# ATSAMG53N19 device description
Architecture: CORTEX-M4; Family: SAMG; Series: SAMG53
Registers are 32-bit, read-write, no defined reset value unless marked. A register's access mark holds for its fields unless they carry their own. Offsets are from the block's base; [hi:lo] are bit positions; {n}, {i} and the like mark numbered series; 'fields as' and 'values as' point back to an identical list; <NAME> marks a mode.

## USART — Universal Synchronous Asynchronous Receiver Transmitter
Instances: USART 0x40024000
0x00 US_CR wo (modes: USART when US_MR.USART_MODE=None; SPI when US_MR.USART_MODE=None) — Control Register
  [19] RCS <SPI> — Release SPI Chip Select
  [18] FCS <SPI> — Force SPI Chip Select
  [8] RSTSTA <SPI> — Reset Status Bits
  [7] TXDIS <SPI> — Transmitter Disable
  [6] TXEN <SPI> — Transmitter Enable
  [5] RXDIS <SPI> — Receiver Disable
  [4] RXEN <SPI> — Receiver Enable
  [3] RSTTX <SPI> — Reset Transmitter
  [2] RSTRX <SPI> — Reset Receiver
  [19] RTSDIS <USART> — Request to Send Disable
  [18] RTSEN <USART> — Request to Send Enable
  [15] RETTO <USART> — Start Timeout Immediately
  [12] SENDA <USART> — Send Address
  [11] STTTO <USART> — Clear TIMEOUT Flag and Start Timeout After Next Character Received
  [10] STPBRK <USART> — Stop Break
  [9] STTBRK <USART> — Start Break
  [8] RSTSTA <USART> — Reset Status Bits
  [7] TXDIS <USART> — Transmitter Disable
  [6] TXEN <USART> — Transmitter Enable
  [5] RXDIS <USART> — Receiver Disable
  [4] RXEN <USART> — Receiver Enable
  [3] RSTTX <USART> — Reset Transmitter
  [2] RSTRX <USART> — Reset Receiver
0x04 US_MR (modes: USART when US_MR.USART_MODE=None; SPI when US_MR.USART_MODE=None) — Mode Register
  [20] WRDBT <SPI> — Wait Read Data Before Transfer
  [18] CLKO <SPI> — Clock Output Select
  [16] CPOL <SPI> — SPI Clock Polarity
  [8] CPHA <SPI> — SPI Clock Phase
  [7:6] CHRL <SPI> — Character Length
    {v}=_{v+5}_BIT (Character length is {v+5} bits) (v=0..3)
  [5:4] USCLKS <SPI> — Clock Selection
    0=MCK (Peripheral clock is selected); 1=DIV (Peripheral clock divided (DIV=8) is selected); 3=SCK (Serial clock (SCK) is selected)
  [3:0] USART_MODE <SPI> — USART Mode of Operation
    0=NORMAL (Normal mode); 1=RS485 (RS485 mode); 2=HW_HANDSHAKING (Hardware Handshaking); 14=SPI_MASTER (SPI master mode); 15=SPI_SLAVE (SPI Slave mode)
  [28] FILTER <USART> — Receive Line Filter
  [19] OVER <USART> — Oversampling Mode
  [18] CLKO <USART> — Clock Output Select
  [17] MODE9 <USART> — 9-bit Character Length
  [15:14] CHMODE <USART> — Channel Mode
    0=NORMAL (Normal mode); 1=AUTOMATIC (Automatic Echo. Receiver input is connected to the TXD pin.); 2=LOCAL_LOOPBACK (Local Loopback. Transmitter output is connected to the Receiver Input.); 3=REMOTE_LOOPBACK (Remote Loopback. RXD pin is internally connected to the TXD pin.)
  [13:12] NBSTOP <USART> — Number of Stop Bits
    0=_1_BIT (1 stop bit); 1=_1_5_BIT (1.5 stop bits (SYNC = 0) or reserved (SYNC = 1)); 2=_2_BIT (2 stop bits)
  [11:9] PAR <USART> — Parity Type
    0=EVEN (Even parity); 1=ODD (Odd parity); 2=SPACE (Parity forced to 0 (Space)); 3=MARK (Parity forced to 1 (Mark)); 4=NO (No parity); 6=MULTIDROP (Multidrop mode)
  [8] SYNC <USART> — Synchronous Mode Select
  [7:6] CHRL <USART> — Character Length
    {v}=_{v+5}_BIT (Character length is {v+5} bits) (v=0..3)
  [5:4] USCLKS <USART> — Clock Selection
    values as USCLKS<SPI>
  [3:0] USART_MODE <USART> — USART Mode of Operation
    values as USART_MODE<SPI>
0x08 US_IER wo (atomic set of US_IMR) (modes: USART when US_MR.USART_MODE=None; SPI when US_MR.USART_MODE=None) — Interrupt Enable Register
  [19] NSSE <SPI> — NSS Line (Driving CTS Pin) Rising or Falling Edge Event Interrupt Enable
  [12] RXBUFF <SPI> — Receive Buffer Full Interrupt Enable
  [11] TXBUFE <SPI> — Transmit Buffer Empty Interrupt Enable
  [10] UNRE <SPI> — SPI Underrun Error Interrupt Enable
  [9] TXEMPTY <SPI> — TXEMPTY Interrupt Enable
  [5] OVRE <SPI> — Overrun Error Interrupt Enable
  [4] ENDTX <SPI> — End of Transmit Buffer Interrupt Enable
  [3] ENDRX <SPI> — End of Receive Buffer Interrupt Enable
  [1] TXRDY <SPI> — TXRDY Interrupt Enable
  [0] RXRDY <SPI> — RXRDY Interrupt Enable
  [19] CTSIC <USART> — Clear to Send Input Change Interrupt Enable
  [12] RXBUFF <USART> — Receive Buffer Full Interrupt Enable (available in all USART modes of operation)
  [11] TXBUFE <USART> — Transmit Buffer Empty Interrupt Enable (available in all USART modes of operation)
  [9] TXEMPTY <USART> — TXEMPTY Interrupt Enable
  [8] TIMEOUT <USART> — Time-out Interrupt Enable
  [7] PARE <USART> — Parity Error Interrupt Enable
  [6] FRAME <USART> — Framing Error Interrupt Enable
  [5] OVRE <USART> — Overrun Error Interrupt Enable
  [4] ENDTX <USART> — End of Transmit Buffer Interrupt Enable (available in all USART modes of operation)
  [3] ENDRX <USART> — End of Receive Buffer Interrupt Enable (available in all USART modes of operation)
  [2] RXBRK <USART> — Receiver Break Interrupt Enable
  [1] TXRDY <USART> — TXRDY Interrupt Enable
  [0] RXRDY <USART> — RXRDY Interrupt Enable
0x0C US_IDR wo (atomic clear of US_IMR) (modes: USART when US_MR.USART_MODE=None; SPI when US_MR.USART_MODE=None) — Interrupt Disable Register
  fields as US_IER
0x10 US_IMR ro (atomic read) (modes: USART when US_MR.USART_MODE=None; SPI when US_MR.USART_MODE=None) — Interrupt Mask Register
  fields as US_IER
0x14 US_CSR ro (modes: USART when US_MR.USART_MODE=None; SPI when US_MR.USART_MODE=None) — Channel Status Register
  [23] NSS <SPI> — Image of NSS Line
  [19] NSSE <SPI> — NSS Line (Driving CTS Pin) Rising or Falling Edge Event (cleared on read)
  [12] RXBUFF <SPI> — RX Buffer Full (cleared by writing US_RCR or US_RNCR)
  [11] TXBUFE <SPI> — TX Buffer Empty (cleared by writing US_TCR or US_TNCR)
  [10] UNRE <SPI> — Underrun Error (cleared by writing a one to bit US_CR.RSTSTA)
  [9] TXEMPTY <SPI> — Transmitter Empty (cleared by writing US_THR)
  [5] OVRE <SPI> — Overrun Error (cleared by writing a one to bit US_CR.RSTSTA)
  [4] ENDTX <SPI> — End of TX Buffer (cleared by writing US_TCR or US_TNCR)
  [3] ENDRX <SPI> — End of RX Buffer (cleared by writing US_RCR or US_RNCR)
  [1] TXRDY <SPI> — Transmitter Ready (cleared by writing US_THR)
  [0] RXRDY <SPI> — Receiver Ready (cleared by reading US_RHR)
  [23] CTS <USART> — Image of CTS Input
  [19] CTSIC <USART> — Clear to Send Input Change Flag (cleared on read)
  [12] RXBUFF <USART> — RX Buffer Full (cleared by writing US_RCR or US_RNCR)
  [11] TXBUFE <USART> — TX Buffer Empty (cleared by writing US_TCR or US_TNCR)
  [9] TXEMPTY <USART> — Transmitter Empty (cleared by writing US_THR)
  [8] TIMEOUT <USART> — Receiver Time-out (cleared by writing a one to bit US_CR.STTTO)
  [7] PARE <USART> — Parity Error (cleared by writing a one to bit US_CR.RSTSTA)
  [6] FRAME <USART> — Framing Error (cleared by writing a one to bit US_CR.RSTSTA)
  [5] OVRE <USART> — Overrun Error (cleared by writing a one to bit US_CR.RSTSTA)
  [4] ENDTX <USART> — End of TX Buffer (cleared by writing US_TCR or US_TNCR)
  [3] ENDRX <USART> — End of RX Buffer (cleared by writing US_RCR or US_RNCR)
  [2] RXBRK <USART> — Break Received/End of Break (cleared by writing a one to bit US_CR.RSTSTA)
  [1] TXRDY <USART> — Transmitter Ready (cleared by writing US_THR)
  [0] RXRDY <USART> — Receiver Ready (cleared by reading US_RHR)
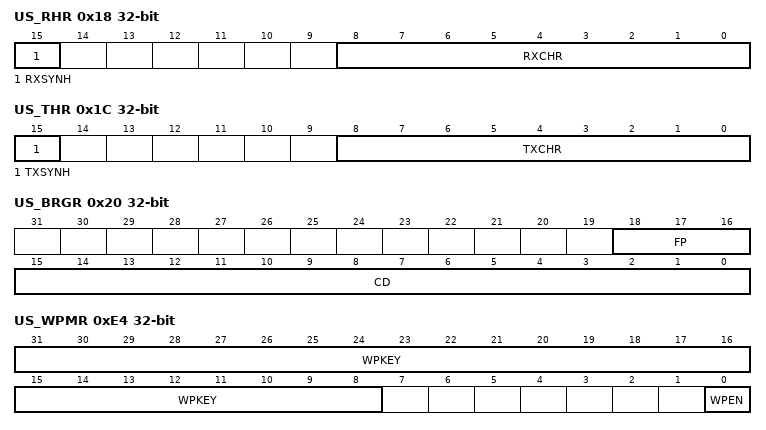
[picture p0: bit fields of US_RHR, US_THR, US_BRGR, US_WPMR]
0x18 US_RHR ro — Receive Holding Register
  [15] RXSYNH — Received Sync
  [8:0] RXCHR — Received Character
0x1C US_THR wo — Transmit Holding Register
  [15] TXSYNH — Sync Field to be Transmitted
  [8:0] TXCHR — Character to be Transmitted
0x20 US_BRGR — Baud Rate Generator Register
  [18:16] FP — Fractional Part
  [15:0] CD — Clock Divider
0x24 US_RTOR — Receiver Time-out Register
  [15:0] TO — Time-out Value
0x28 US_TTGR — Transmitter Timeguard Register
  [7:0] TG — Timeguard Value
0x44 US_NER ro — Number of Errors Register
  [7:0] NB_ERRORS — Number of Errors
0xE4 US_WPMR — Write Protection Mode Register
  [31:8] WPKEY — Write Protection Key
    0x555341=PASSWD (Writing any other value in this field aborts the write operation of the WPEN bit. Always reads as 0.)
  [0] WPEN — Write Protection Enable
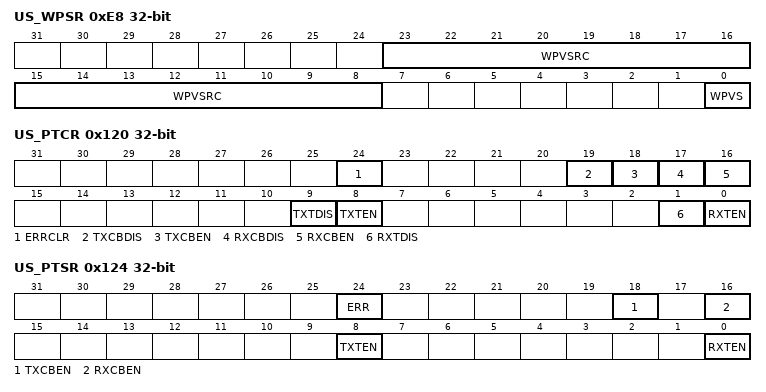
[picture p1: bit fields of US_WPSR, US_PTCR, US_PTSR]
0xE8 US_WPSR ro — Write Protection Status Register
  [23:8] WPVSRC — Write Protection Violation Source
  [0] WPVS — Write Protection Violation Status
0x100 US_RPR — Receive Pointer Register
  [31:0] RXPTR
0x104 US_RCR — Receive Counter Register
  [15:0] RXCTR
0x108 US_TPR — Transmit Pointer Register
  [31:0] TXPTR — Transmit Counter Register
0x10C US_TCR — Transmit Counter Register
  [15:0] TXCTR
0x110 US_RNPR — Receive Next Pointer Register
  [31:0] RXNPTR — Receive Next Pointer
0x114 US_RNCR — Receive Next Counter Register
  [15:0] RXNCTR — Receive Next Counter
0x118 US_TNPR — Transmit Next Pointer Register
  [31:0] TXNPTR — Transmit Next Pointer
0x11C US_TNCR — Transmit Next Counter Register
  [15:0] TXNCTR — Transmit Counter Next
0x120 US_PTCR wo — Transfer Control Register
  [24] ERRCLR — Transfer Bus Error Clear
  [19] TXCBDIS — Transmitter Circular Buffer Disable
  [18] TXCBEN — Transmitter Circular Buffer Enable
  [17] RXCBDIS — Receiver Circular Buffer Disable
  [16] RXCBEN — Receiver Circular Buffer Enable
  [9] TXTDIS — Transmitter Transfer Disable
  [8] TXTEN — Transmitter Transfer Enable
  [1] RXTDIS — Receiver Transfer Disable
  [0] RXTEN — Receiver Transfer Enable
0x124 US_PTSR ro — Transfer Status Register
  [24] ERR — Transfer Bus Error
  [18] TXCBEN — Transmitter Circular Buffer Enable
  [16] RXCBEN — Receiver Circular Buffer Enable
  [8] TXTEN — Transmitter Transfer Enable
  [0] RXTEN — Receiver Transfer Enable

## Notices in the file
Copyright (c) 2017 Microchip Technology Inc.
SPDX-License-Identifier: Apache-2.0
Licensed under the Apache License, Version 2.0 (the "License");
you may not use this file except in compliance with the License.
You may obtain a copy of the License at
http://www.apache.org/licenses/LICENSE-2.0
Unless required by applicable law or agreed to in writing, software
distributed under the License is distributed on an "AS IS" BASIS,
WITHOUT WARRANTIES OR CONDITIONS OF ANY KIND, either express or implied.
See the License for the specific language governing permissions and
limitations under the License.
